# LKS32MC07x register map
Vendor: Linko Ltd.; Series: LKS32MC07x; File version: 1.0
ARM 32-bit Cortex-M0 Microcontroller based device
CPU: CM0 r1p0, little endian, MPU, no FPU, 3 interrupt priority bits
Registers are 32-bit, read-write, reset 0x0 unless marked. A register's access mark holds for its fields unless they carry their own. Offsets are from the block's base; lines under a group give offsets from that group; [hi:lo] are bit positions; {n}, {i} and the like mark numbered series; 'fields as' and 'values as' point back to an identical list; <NAME> marks a mode.

## Memory map
0x00020000 FLASH size 0x40 — FLASH registers
0x40000000 SYS size 0x100 — SYS registers
0x40010000 SPI0 size 0x100 — SPI0 registers
0x40010100 I2C0 size 0x100 — I2C0 registers
0x40010200 CMP size 0x20 — CMP registers
0x40010300 HALL0 size 0x100 — HALL0 registers
0x40010400 ADC0 size 0x100 — ADC0 registers
0x40010500 ADC1 size 0x100 — ADC1 registers
0x40010600 TIMER0 size 0x30 — TIMER0 registers
0x40010700 TIMER1 size 0x30 — TIMER1 registers
0x40010800 TIMER2 size 0x30 — TIMER2 registers
0x40010900 TIMER3 size 0x30 — TIMER3 registers
0x40010A00 QEP0 size 0x10 — QEP0 registers
0x40010B00 QEP1 size 0x10 — QEP1 registers
0x40010C00 MCPWM0 size 0x100 — MCPWM0 registers
0x40010D00 GPIO0 size 0x40 — GPIO0 registers
0x40010D40 GPIO1 size 0x40 — GPIO1 registers
0x40010D80 GPIO2 size 0x40 — GPIO2 registers
0x40010DC0 GPIO3 size 0x40 — GPIO3 registers
0x40010E00 EXTI size 0x40 — EXTI registers
0x40010F00 CRC0 size 0x100 — CRC0 registers
0x40011000 UART0 size 0x100 — UART0 registers
0x40011100 UART1 size 0x100 — UART1 registers
0x40011200 DMA0 size 0x100 — DMA0 registers
0x40011300 CAN0 size 0x200 — CAN0 registers
0x40011500 SIF0 size 0x100 — SIF0 registers
0x40011700 IWDG size 0x20 — IWDG registers
0x40011720 AON size 0x10 — AON registers
0x40011800 CL0 size 0x20 — CL0 registers
0x40012000 DSP0 size 0x2000 — DSP0 registers

## Interrupts
0 TIMER0
1 TIMER1
2 TIMER2
3 TIMER3
4 QEP0
5 QEP1
6 I2C0
7 SPI0
9 HALL0
10 UART0
11 UART1
12 DSP0
14 ADC0
15 ADC1
16 MCPWM0
17 MCPWM1 (MCPWM0)
18 DMA0
19 CAN0
20 SIF0
21 WAKE (SYS)
22 SW (SYS)
23 PWRDN (SYS)
24 CL0

## FLASH — FLASH registers
Base 0x00020000
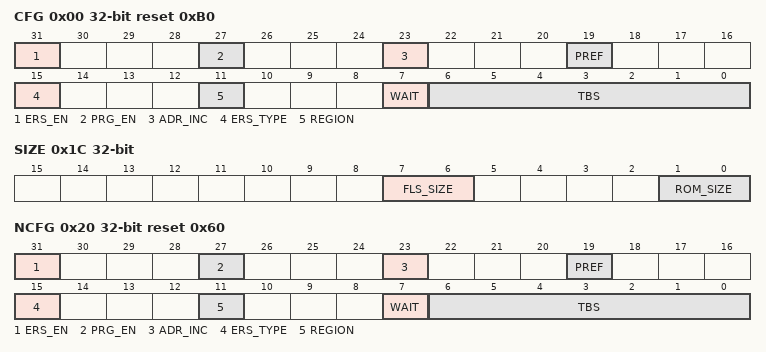
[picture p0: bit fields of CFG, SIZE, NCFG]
0x00 CFG reset 0xB0 — Flash Configure Register
  [31] ERS_EN — Flash erase operation is enabled or not
    0=DISABLED (Erase is disabled); 1=ENABLED (Erase is enabled)
  [27] PRG_EN — Flash program operation is enabled or not
    0=DISABLED (Program is disabled); 1=ENABLED (Program is enabled)
  [23] ADR_INC — Flash address is incremented automatically or not during sequent access
    0=DISABLED (Address incrementation is disabled); 1=ENABLED (Address incrementation is enabled)
  [19] PREF — Prefetch Function Enable or Disable
    0=DISABLED (Prefetch is disabled); 1=ENABLED (Prefetch is enabled)
  [15] ERS_TYPE — Erase Type: Sector/Full
    0=SECTOR (Sector Erase); 1=FULL (Full Erase)
  [11] REGION — Access Main or NVR
    0=MAIN (Main access); 1=NVR (NVR access)
  [7] WAIT — Wait for Flash Read Data
    0=ONE (Wati for one period); 1=TWO (Wati for two periods)
  [6:0] TBS — Program/Erase timer baseline
    96=96MHZ (P/E Timer value @ 96Mhz); 48=48MHZ (P/E Timer value @ 48Mhz); 23=24MHZ (P/E Timer value @ 24Mhz)
0x04 ADDR — Flash Access Address Register
  [14:0] ADDR
0x08 WDATA wo — Flash Write Data Register
0x0C RDATA ro — Flash Read Data Register
0x10 ERASE wo — Flash Erase Register(Write 0x7654DCBA to Trig Erase Operation)
0x14 PROTECT ro — Read to update Flash Protection Status
0x18 READY ro reset not defined — Flash Busy/Idle Status
  [0] READY
    0=BUSY (Flash is Busy); 1=IDLE (Flash is Idle)
0x1C SIZE ro reset not defined — Flash Size Register
  [7:6] FLS_SIZE — Flash Size
    0=32KB; 1=64KB; 2=128KB; 3=128KB
  [1:0] ROM_SIZE
    0=0KB; 1=32KB; 2=64KB
0x20 NCFG reset 0x60 — Flash NVR Configure Register
  [31] ERS_EN — Flash erase operation is enabled or not
    0=DISABLED (Erase is disabled); 1=ENABLED (Erase is enabled)
  [27] PRG_EN — Flash program operation is enabled or not
    values as CFG.PRG_EN
  [23] ADR_INC ro — Flash address is incremented automatically or not during sequent access
    values as CFG.ADR_INC
  [19] PREF — Prefetch Function Enable or Disable
    values as CFG.PREF
  [15] ERS_TYPE ro — Erase Type: Sector/Full
    0=SECTOR (Sector Erase); 1=FULL (Full Erase)
  [11] REGION — Access Main or NVR
    0=MAIN (Main access); 1=NVR (NVR access)
  [7] WAIT ro — Wait for Flash Read Data
    0=ONE (Wati for one period); 1=TWO (Wati for two periods)
  [6:0] TBS ro — Program/Erase timer baseline
    96=96MHZ (P/E Timer value @ 96Mhz); 47=48MHZ (P/E Timer value @ 48Mhz); 23=24MHZ (P/E Timer value @ 24Mhz)
0x24 NADDR — Flash NVR Access Address Register
  [14:0] ADDR
0x28 NWDATA wo — Flash NVR Write Data Register
0x2C NRDATA ro — Flash NVR Read Data Register
0x30 NERASE wo — Flash NVR Erase Register(Write 0x7654DCBA to Trig Erase Operation)
0x34 NKEY wo — Flash NVR Key Register
  [3:0] KEY — Flash Key Register, when Flash is protected, write 0x0000_000F to this reg, enable write, program and erase for NVR Sector 2

## Licence text in the file
ARM Limited (ARM) is supplying this software for use with Cortex-M processor based microcontroller, but can be equally used for other suitable processor architectures. This file can be freely distributed. Modifications to this file shall be clearly marked. . THIS SOFTWARE IS PROVIDED "AS IS". NO WARRANTIES, WHETHER EXPRESS, IMPLIED. OR STATUTORY, INCLUDING, BUT NOT LIMITED TO, IMPLIED WARRANTIES OF. MERCHANTABILITY AND FITNESS FOR A PARTICULAR PURPOSE APPLY TO THIS SOFTWARE. ARM SHALL NOT, IN ANY CIRCUMSTANCES, BE LIABLE FOR SPECIAL, INCIDENTAL, OR. CONSEQUENTIAL DAMAGES, FOR ANY REASON WHATSOEVER.

## Notices in the file
Copyright (C) 2012-2014 ARM Limited. All rights reserved.
Purpose: System Viewer Description (SVD) Example (Schema Version 1.1)
This is a description of a none-existent and incomplete device
for demonstration purposes only.
Redistribution and use in source and binary forms, with or without
modification, are permitted provided that the following conditions are met:
- Redistributions of source code must retain the above copyright
notice, this list of conditions and the following disclaimer.
- Redistributions in binary form must reproduce the above copyright
notice, this list of conditions and the following disclaimer in the
documentation and/or other materials provided with the distribution.
- Neither the name of ARM nor the names of its contributors may be used
to endorse or promote products derived from this software without
specific prior written permission.
THIS SOFTWARE IS PROVIDED BY THE COPYRIGHT HOLDERS AND CONTRIBUTORS "AS IS"
AND ANY EXPRESS OR IMPLIED WARRANTIES, INCLUDING, BUT NOT LIMITED TO, THE
ARE DISCLAIMED. IN NO EVENT SHALL COPYRIGHT HOLDERS AND CONTRIBUTORS BE
LIABLE FOR ANY DIRECT, INDIRECT, INCIDENTAL, SPECIAL, EXEMPLARY, OR
CONSEQUENTIAL DAMAGES (INCLUDING, BUT NOT LIMITED TO, PROCUREMENT OF
SUBSTITUTE GOODS OR SERVICES; LOSS OF USE, DATA, OR PROFITS; OR BUSINESS
INTERRUPTION) HOWEVER CAUSED AND ON ANY THEORY OF LIABILITY, WHETHER IN
CONTRACT, STRICT LIABILITY, OR TORT (INCLUDING NEGLIGENCE OR OTHERWISE)
ARISING IN ANY WAY OUT OF THE USE OF THIS SOFTWARE, EVEN IF ADVISED OF THE
POSSIBILITY OF SUCH DAMAGE.
